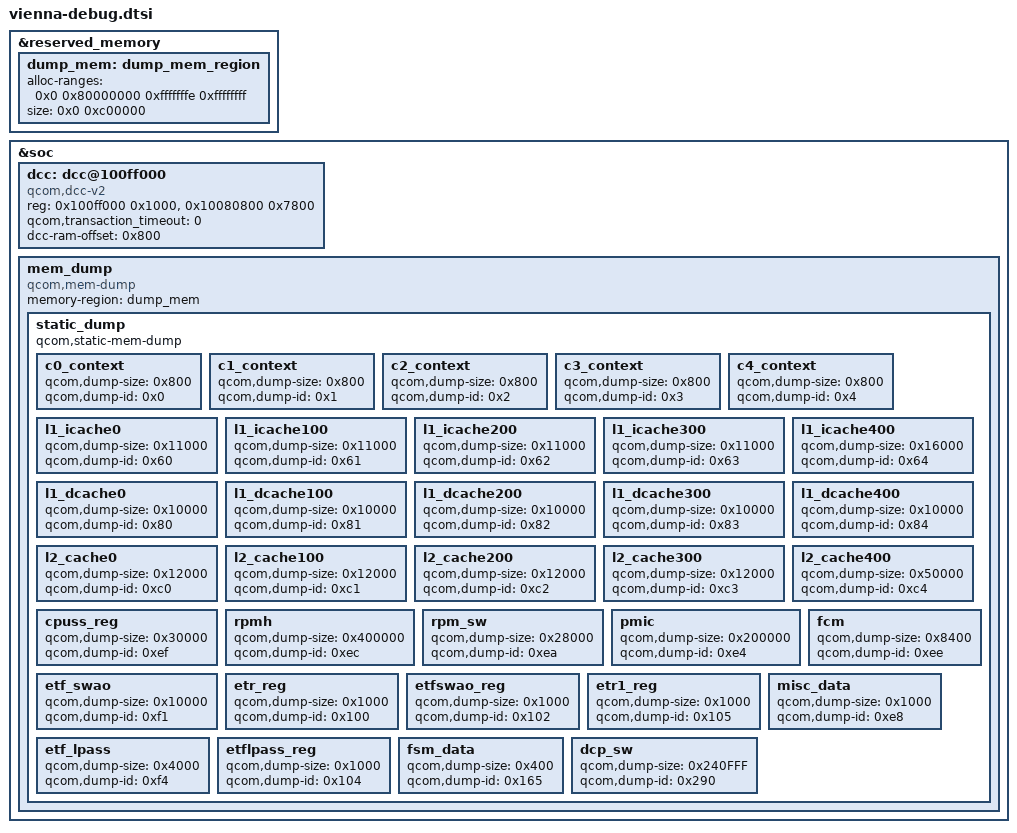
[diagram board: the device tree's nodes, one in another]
// SPDX-License-Identifier: BSD-3-Clause
/*
 * Copyright (c) Qualcomm Technologies, Inc. and/or its subsidiaries.
 */

#include <dt-bindings/soc/qcom,dcc_v2.h>

&reserved_memory {
	#address-cells = <2>;
	#size-cells = <2>;
	ranges;

	dump_mem: dump_mem_region {
		alloc-ranges = <0x0 0x80000000 0xfffffffe 0xffffffff>;
		size = <0x0 0xc00000>;
	};
};

&soc {
	dcc: dcc@100ff000 {
		compatible = "qcom,dcc-v2";
		reg = <0x100ff000 0x1000>,
		      <0x10080800 0x7800>;
		reg-names = "dcc-base", "dcc-ram-base";

		qcom,transaction_timeout = <0>;
		dcc-ram-offset = <0x800>;
	};

	mem_dump {
		compatible = "qcom,mem-dump";
		memory-region = <&dump_mem>;

		static_dump {
			qcom,static-mem-dump;

			c0_context {
					qcom,dump-size = <0x800>;
					qcom,dump-id = <0x0>;
			};

			c1_context {
					qcom,dump-size = <0x800>;
					qcom,dump-id = <0x1>;
			};

			c2_context {
					qcom,dump-size = <0x800>;
					qcom,dump-id = <0x2>;
			};

			c3_context {
					qcom,dump-size = <0x800>;
					qcom,dump-id = <0x3>;
			};

			c4_context {
					qcom,dump-size = <0x800>;
					qcom,dump-id = <0x4>;
			};

			l1_icache0 {
				qcom,dump-size = <0x11000>;
				qcom,dump-id = <0x60>;
			};

			l1_icache100 {
				qcom,dump-size = <0x11000>;
				qcom,dump-id = <0x61>;
			};

			l1_icache200 {
				qcom,dump-size = <0x11000>;
				qcom,dump-id = <0x62>;
			};

			l1_icache300 {
				qcom,dump-size = <0x11000>;
				qcom,dump-id = <0x63>;
			};

			l1_icache400 {
				qcom,dump-size = <0x16000>;
				qcom,dump-id = <0x64>;
				};

			l1_dcache0 {
				qcom,dump-size = <0x10000>;
				qcom,dump-id = <0x80>;
			};

			l1_dcache100 {
				qcom,dump-size = <0x10000>;
				qcom,dump-id = <0x81>;
			};

			l1_dcache200 {
				qcom,dump-size = <0x10000>;
				qcom,dump-id = <0x82>;
			};

			l1_dcache300 {
				qcom,dump-size = <0x10000>;
				qcom,dump-id = <0x83>;
			};

			l1_dcache400 {
				qcom,dump-size = <0x10000>;
				qcom,dump-id = <0x84>;
			};

			l2_cache0 {
				qcom,dump-size = <0x12000>;
				qcom,dump-id = <0xc0>;
			};

			l2_cache100 {
				qcom,dump-size = <0x12000>;
				qcom,dump-id = <0xc1>;
			};

			l2_cache200 {
				qcom,dump-size = <0x12000>;
				qcom,dump-id = <0xc2>;
			};

			l2_cache300 {
				qcom,dump-size = <0x12000>;
				qcom,dump-id = <0xc3>;
			};

			l2_cache400 {
				qcom,dump-size = <0x50000>;
				qcom,dump-id = <0xc4>;
			};

			cpuss_reg {
				qcom,dump-size = <0x30000>;
				qcom,dump-id = <0xef>;
			};

			rpmh {
				qcom,dump-size = <0x400000>;
				qcom,dump-id = <0xec>;
			};

			rpm_sw {
				qcom,dump-size = <0x28000>;
				qcom,dump-id = <0xea>;
			};

			pmic {
				qcom,dump-size = <0x200000>;
				qcom,dump-id = <0xe4>;
			};

			fcm {
				qcom,dump-size = <0x8400>;
				qcom,dump-id = <0xee>;
			};

			etf_swao {
				qcom,dump-size = <0x10000>;
				qcom,dump-id = <0xf1>;
			};

			etr_reg {
				qcom,dump-size = <0x1000>;
				qcom,dump-id = <0x100>;
			};

			etfswao_reg {
				qcom,dump-size = <0x1000>;
				qcom,dump-id = <0x102>;
			};

			etr1_reg {
				qcom,dump-size = <0x1000>;
				qcom,dump-id = <0x105>;
			};

			misc_data {
				qcom,dump-size = <0x1000>;
				qcom,dump-id = <0xe8>;
			};

			etf_lpass {
				qcom,dump-size = <0x4000>;
				qcom,dump-id = <0xf4>;
			};

			etflpass_reg {
				qcom,dump-size = <0x1000>;
				qcom,dump-id = <0x104>;
			};

			fsm_data {
				qcom,dump-size = <0x400>;
				qcom,dump-id = <0x165>;
			};

			dcp_sw {
				qcom,dump-size = <0x240FFF>;
				qcom,dump-id = <0x290>;
			};
		};
	};
};
